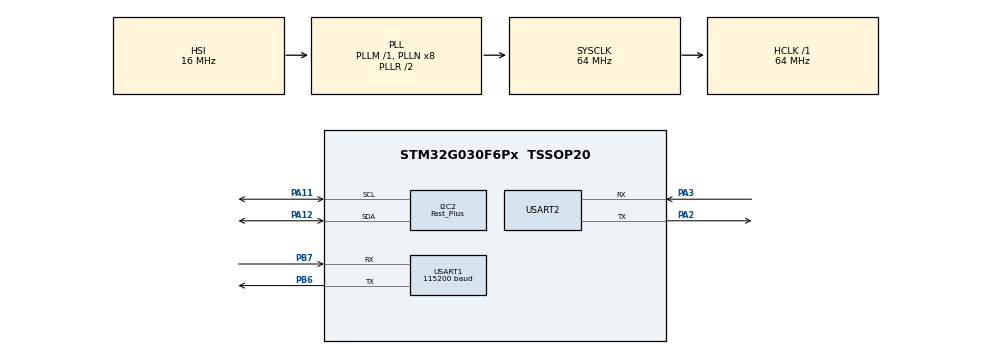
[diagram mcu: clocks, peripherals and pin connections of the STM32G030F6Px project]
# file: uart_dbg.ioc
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Dma.Request0=USART2_RX
Dma.Request1=USART1_RX
Dma.USART1_RX.1.Direction=DMA_PERIPH_TO_MEMORY
Dma.USART1_RX.1.EventEnable=DISABLE
Dma.USART1_RX.1.Instance=DMA1_Channel2
Dma.USART1_RX.1.MemDataAlignment=DMA_MDATAALIGN_BYTE
Dma.USART1_RX.1.MemInc=DMA_MINC_ENABLE
Dma.USART1_RX.1.Mode=DMA_NORMAL
Dma.USART1_RX.1.PeriphDataAlignment=DMA_PDATAALIGN_BYTE
Dma.USART1_RX.1.PeriphInc=DMA_PINC_DISABLE
Dma.USART1_RX.1.Polarity=HAL_DMAMUX_REQ_GEN_RISING
Dma.USART1_RX.1.Priority=DMA_PRIORITY_LOW
Dma.USART1_RX.1.RequestNumber=1
Dma.USART1_RX.1.SignalID=NONE
Dma.USART1_RX.1.SyncEnable=DISABLE
Dma.USART1_RX.1.SyncPolarity=HAL_DMAMUX_SYNC_NO_EVENT
Dma.USART1_RX.1.SyncRequestNumber=1
Dma.USART1_RX.1.SyncSignalID=NONE
Dma.USART2_RX.0.Direction=DMA_PERIPH_TO_MEMORY
Dma.USART2_RX.0.EventEnable=DISABLE
Dma.USART2_RX.0.Instance=DMA1_Channel1
Dma.USART2_RX.0.MemDataAlignment=DMA_MDATAALIGN_BYTE
Dma.USART2_RX.0.MemInc=DMA_MINC_ENABLE
Dma.USART2_RX.0.Mode=DMA_NORMAL
Dma.USART2_RX.0.PeriphDataAlignment=DMA_PDATAALIGN_BYTE
Dma.USART2_RX.0.PeriphInc=DMA_PINC_DISABLE
Dma.USART2_RX.0.Polarity=HAL_DMAMUX_REQ_GEN_RISING
Dma.USART2_RX.0.Priority=DMA_PRIORITY_LOW
Dma.USART2_RX.0.RequestNumber=1
Dma.USART2_RX.0.SignalID=NONE
Dma.USART2_RX.0.SyncEnable=DISABLE
Dma.USART2_RX.0.SyncPolarity=HAL_DMAMUX_SYNC_NO_EVENT
Dma.USART2_RX.0.SyncRequestNumber=1
Dma.USART2_RX.0.SyncSignalID=NONE
I2C2.I2C_Speed_Mode=I2C_Fast_Plus
I2C2.Timing=0x00300B29
Mcu.Family=STM32G0
Mcu.Name=STM32G030F6Px
Mcu.Package=TSSOP20
NVIC.DMA1_Channel1_IRQn=true\:0\:0\:false\:false\:true\:false\:true
NVIC.DMA1_Channel2_3_IRQn=true\:0\:0\:false\:false\:true\:false\:true
NVIC.TIM14_IRQn=true\:0\:0\:false\:false\:true\:true\:true
NVIC.USART1_IRQn=true\:0\:0\:false\:false\:true\:true\:true
NVIC.USART2_IRQn=true\:0\:0\:false\:false\:true\:true\:true
PA11\ [PA9].Mode=I2C
PA11\ [PA9].Signal=I2C2_SCL
PA12\ [PA10].Mode=I2C
PA12\ [PA10].Signal=I2C2_SDA
PA13.Mode=Serial_Wire
PA13.Signal=SYS_SWDIO
PA14-BOOT0.Mode=Serial_Wire
PA14-BOOT0.Signal=SYS_SWCLK
PA2.Mode=Asynchronous
PA2.Signal=USART2_TX
PA3.Mode=Asynchronous
PA3.Signal=USART2_RX
PB6.Mode=Asynchronous
PB6.Signal=USART1_TX
PB7.Mode=Asynchronous
PB7.Signal=USART1_RX
ProjectManager.HeapSize=0x200
ProjectManager.StackSize=0x400
ProjectManager.TargetToolchain=STM32CubeIDE
RCC.ADCFreq_Value=64000000
RCC.AHBFreq_Value=64000000
RCC.CortexFreq_Value=64000000
RCC.EXTERNAL_CLOCK_VALUE=12288000
RCC.HCLKFreq_Value=64000000
RCC.HSE_VALUE=8000000
RCC.HSI_VALUE=16000000
RCC.LSE_VALUE=32768
RCC.SYSCLKFreq_VALUE=64000000
RCC.SYSCLKSource=RCC_SYSCLKSOURCE_PLLCLK
RCC.VCOOutputFreq_Value=128000000
TIM14.Period=99
TIM14.Prescaler=63
USART1.BaudRate=115200
USART1.VirtualMode-Asynchronous=VM_ASYNC
USART2.VirtualMode-Asynchronous=VM_ASYNC
VP_TIM14_VS_ClockSourceINT.Mode=Enable_Timer
board=custom

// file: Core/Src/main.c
/* USER CODE BEGIN Header */
/**
  ******************************************************************************
  * @file           : main.c
  * @brief          : Main program body
  ******************************************************************************
  * @attention
  *
  * <h2><center>&copy; Copyright (c) 2021 STMicroelectronics.
  * All rights reserved.</center></h2>
  *
  * This software component is licensed by ST under BSD 3-Clause license,
  * the "License"; You may not use this file except in compliance with the
  * License. You may obtain a copy of the License at:
  *                        opensource.org/licenses/BSD-3-Clause
  *
  ******************************************************************************
  */
/* USER CODE END Header */
#include "main.h"
#include "dma.h"
#include "i2c.h"
#include "tim.h"
#include "usart.h"
#include "gpio.h"

void SystemClock_Config(void);

int main(void)
{

  /* MCU Configuration--------------------------------------------------------*/

  /* Reset of all peripherals, Initializes the Flash interface and the Systick. */
  HAL_Init();

  /* Configure the system clock */
  SystemClock_Config();

  /* Initialize all configured peripherals */
  MX_GPIO_Init();
  MX_USART1_UART_Init();
  MX_DMA_Init();
  MX_USART2_UART_Init();
  MX_I2C2_Init();
  MX_TIM14_Init();
  /* USER CODE BEGIN 2 */
  void system_run();
  system_run();
  /* USER CODE END 2 */

  /* Infinite loop */
  while (1)
  {

  }
}

void SystemClock_Config(void)
{
  RCC_OscInitTypeDef RCC_OscInitStruct = {0};
  RCC_ClkInitTypeDef RCC_ClkInitStruct = {0};
  RCC_PeriphCLKInitTypeDef PeriphClkInit = {0};

  /** Configure the main internal regulator output voltage
  */
  HAL_PWREx_ControlVoltageScaling(PWR_REGULATOR_VOLTAGE_SCALE1);
  /** Initializes the RCC Oscillators according to the specified parameters
  * in the RCC_OscInitTypeDef structure.
  */
  RCC_OscInitStruct.OscillatorType = RCC_OSCILLATORTYPE_HSI;
  RCC_OscInitStruct.HSIState = RCC_HSI_ON;
  RCC_OscInitStruct.HSIDiv = RCC_HSI_DIV1;
  RCC_OscInitStruct.HSICalibrationValue = RCC_HSICALIBRATION_DEFAULT;
  RCC_OscInitStruct.PLL.PLLState = RCC_PLL_ON;
  RCC_OscInitStruct.PLL.PLLSource = RCC_PLLSOURCE_HSI;
  RCC_OscInitStruct.PLL.PLLM = RCC_PLLM_DIV1;
  RCC_OscInitStruct.PLL.PLLN = 8;
  RCC_OscInitStruct.PLL.PLLP = RCC_PLLP_DIV2;
  RCC_OscInitStruct.PLL.PLLR = RCC_PLLR_DIV2;
  if (HAL_RCC_OscConfig(&RCC_OscInitStruct) != HAL_OK)
  {
    Error_Handler();
  }
  /** Initializes the CPU, AHB and APB buses clocks
  */
  RCC_ClkInitStruct.ClockType = RCC_CLOCKTYPE_HCLK|RCC_CLOCKTYPE_SYSCLK
                              |RCC_CLOCKTYPE_PCLK1;
  RCC_ClkInitStruct.SYSCLKSource = RCC_SYSCLKSOURCE_PLLCLK;
  RCC_ClkInitStruct.AHBCLKDivider = RCC_SYSCLK_DIV1;
  RCC_ClkInitStruct.APB1CLKDivider = RCC_HCLK_DIV1;

  if (HAL_RCC_ClockConfig(&RCC_ClkInitStruct, FLASH_LATENCY_2) != HAL_OK)
  {
    Error_Handler();
  }
  /** Initializes the peripherals clocks
  */
  PeriphClkInit.PeriphClockSelection = RCC_PERIPHCLK_USART1;
  PeriphClkInit.Usart1ClockSelection = RCC_USART1CLKSOURCE_PCLK1;
  if (HAL_RCCEx_PeriphCLKConfig(&PeriphClkInit) != HAL_OK)
  {
    Error_Handler();
  }
}

void Error_Handler(void)
{
  __disable_irq();
  while (1)
  {
  }
}

/************************ (C) COPYRIGHT STMicroelectronics *****END OF FILE****/
